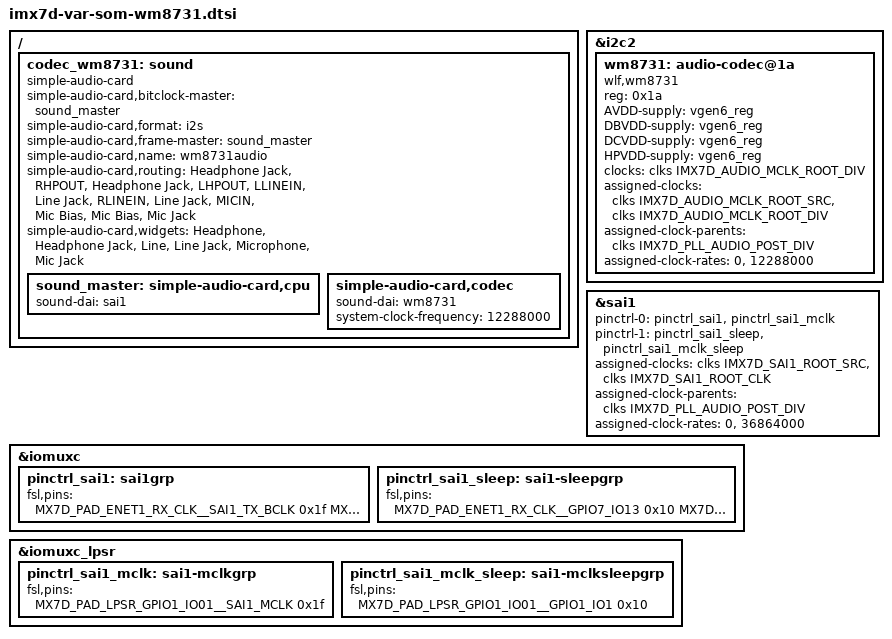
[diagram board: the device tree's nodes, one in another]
// SPDX-License-Identifier: (GPL-2.0+ OR MIT)
/*
 * Common dtsi for WM8731 support on Variscite VAR-SOM-MX7
 *
 * Link: https://variscite.com/system-on-module-som/i-mx-7/var-som-mx7/
 *
 * Copyright (C) 2026 Variscite Ltd. - https://www.variscite.com/
 *
 */

/ {
	codec_wm8731: sound {
		compatible = "simple-audio-card";
		simple-audio-card,bitclock-master = <&sound_master>;
		simple-audio-card,format = "i2s";
		simple-audio-card,frame-master = <&sound_master>;
		simple-audio-card,name = "wm8731audio";
		simple-audio-card,routing =
			"Headphone Jack", "RHPOUT",
			"Headphone Jack", "LHPOUT",
			"LLINEIN", "Line Jack",
			"RLINEIN", "Line Jack",
			"MICIN", "Mic Bias",
			"Mic Bias", "Mic Jack";
		simple-audio-card,widgets =
			"Headphone", "Headphone Jack",
			"Line", "Line Jack",
			"Microphone", "Mic Jack";

		sound_master: simple-audio-card,cpu {
			sound-dai = <&sai1>;
		};

		simple-audio-card,codec {
			sound-dai = <&wm8731>;
			system-clock-frequency = <12288000>;
		};
	};
};

&i2c2 {
	wm8731: audio-codec@1a {
		compatible = "wlf,wm8731";
		reg = <0x1a>;
		#sound-dai-cells = <0>;
		AVDD-supply = <&vgen6_reg>;
		DBVDD-supply = <&vgen6_reg>;
		DCVDD-supply = <&vgen6_reg>;
		HPVDD-supply = <&vgen6_reg>;
		clocks = <&clks IMX7D_AUDIO_MCLK_ROOT_DIV>;
		clock-names = "mclk";
		assigned-clocks = <&clks IMX7D_AUDIO_MCLK_ROOT_SRC>,
				  <&clks IMX7D_AUDIO_MCLK_ROOT_DIV>;
		assigned-clock-parents = <&clks IMX7D_PLL_AUDIO_POST_DIV>;
		assigned-clock-rates = <0>, <12288000>;
	};
};

&sai1 {
	pinctrl-names = "default", "sleep";
	pinctrl-0 = <&pinctrl_sai1>, <&pinctrl_sai1_mclk>;
	pinctrl-1 = <&pinctrl_sai1_sleep>, <&pinctrl_sai1_mclk_sleep>;
	assigned-clocks = <&clks IMX7D_SAI1_ROOT_SRC>,
			  <&clks IMX7D_SAI1_ROOT_CLK>;
	assigned-clock-parents = <&clks IMX7D_PLL_AUDIO_POST_DIV>;
	assigned-clock-rates = <0>, <36864000>;
	status = "okay";
};

&iomuxc {
	pinctrl_sai1: sai1grp {
		fsl,pins = <
			MX7D_PAD_ENET1_RX_CLK__SAI1_TX_BCLK		0x1f
			MX7D_PAD_ENET1_CRS__SAI1_TX_SYNC		0x1f
			MX7D_PAD_ENET1_COL__SAI1_TX_DATA0		0x30
			MX7D_PAD_ENET1_TX_CLK__SAI1_RX_DATA0		0x1f
		>;
	};

	pinctrl_sai1_sleep: sai1-sleepgrp {
		fsl,pins = <
			MX7D_PAD_ENET1_RX_CLK__GPIO7_IO13		0x10
			MX7D_PAD_ENET1_CRS__GPIO7_IO14			0x10
			MX7D_PAD_ENET1_COL__GPIO7_IO15			0x10
			MX7D_PAD_ENET1_TX_CLK__GPIO7_IO12		0x10
		>;
	};
};

&iomuxc_lpsr {
	pinctrl_sai1_mclk: sai1-mclkgrp {
		fsl,pins = <
			MX7D_PAD_LPSR_GPIO1_IO01__SAI1_MCLK		0x1f
		>;
	};

	pinctrl_sai1_mclk_sleep: sai1-mclksleepgrp {
		fsl,pins = <
			MX7D_PAD_LPSR_GPIO1_IO01__GPIO1_IO1		0x10
		>;
	};
};
